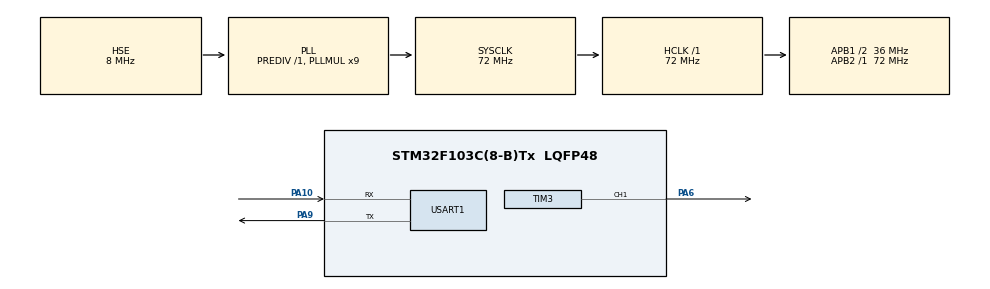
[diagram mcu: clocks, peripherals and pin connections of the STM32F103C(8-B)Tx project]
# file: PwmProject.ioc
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Mcu.Family=STM32F1
RCC.PLLSourceVirtual=RCC_PLLSOURCE_HSE
PD1-OSC_OUT.Mode=HSE-External-Oscillator
PA10.Mode=Asynchronous
PD0-OSC_IN.Signal=RCC_OSC_IN
RCC.APB1CLKDivider=RCC_HCLK_DIV2
RCC.SYSCLKSource=RCC_SYSCLKSOURCE_PLLCLK
ProjectManager.StackSize=0x400
PD1-OSC_OUT.Signal=RCC_OSC_OUT
PA13.Signal=SYS_JTMS-SWDIO
PA9.Mode=Asynchronous
ProjectManager.TargetToolchain=STM32CubeIDE
RCC.HCLKFreq_Value=72000000
RCC.APB2TimFreq_Value=72000000
TIM3.Period=199
PA9.Signal=USART1_TX
RCC.USBFreq_Value=72000000
RCC.AHBFreq_Value=72000000
TIM3.Channel-PWM\ Generation1\ CH1=TIM_CHANNEL_1
PD0-OSC_IN.Mode=HSE-External-Oscillator
board=custom
RCC.PLLMUL=RCC_PLL_MUL9
RCC.APB2Freq_Value=72000000
PA14.Mode=Serial_Wire
TIM3.Prescaler=7199
SH.S_TIM3_CH1.0=TIM3_CH1,PWM Generation1 CH1
PA13.Mode=Serial_Wire
Mcu.Name=STM32F103C(8-B)Tx
RCC.SYSCLKFreq_VALUE=72000000
Mcu.Package=LQFP48
PA6.Signal=S_TIM3_CH1
USART1.VirtualMode=VM_ASYNC
PA10.Signal=USART1_RX
PA14.Signal=SYS_JTCK-SWCLK
ProjectManager.HeapSize=0x200
NVIC.PriorityGroup=NVIC_PRIORITYGROUP_4
RCC.APB1TimFreq_Value=72000000
NVIC.USART1_IRQn=true\:0\:0\:false\:false\:true\:true\:true
RCC.APB1Freq_Value=36000000
VP_TIM3_VS_ClockSourceINT.Mode=Internal

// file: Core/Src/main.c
/* USER CODE BEGIN Header */
/**
  ******************************************************************************
  * @file           : main.c
  * @brief          : Main program body
  ******************************************************************************
  * @attention
  *
  * <h2><center>&copy; Copyright (c) 2021 STMicroelectronics.
  * All rights reserved.</center></h2>
  *
  * This software component is licensed by ST under BSD 3-Clause license,
  * the "License"; You may not use this file except in compliance with the
  * License. You may obtain a copy of the License at:
  *                        opensource.org/licenses/BSD-3-Clause
  *
  ******************************************************************************
  */
/* USER CODE END Header */
#include "main.h"
#include "tim.h"
#include "usart.h"
#include "gpio.h"

/* USER CODE BEGIN Includes */
void Servo_Control(uint16_t angle){
	float temp;
	temp = (1.0 / 9.0) * angle + 5.0; // 占空比 = 1/9 * 角度 +5
	__HAL_TIM_SET_COMPARE(&htim3,TIM_CHANNEL_1,(uint16_t)temp);
}
/* USER CODE END Includes */

void SystemClock_Config(void);

/* USER CODE BEGIN 0 */
uint8_t RxBuffer[1];
uint8_t mode,dir,count;
/* USER CODE END 0 */

int main(void)
{

  /* MCU Configuration--------------------------------------------------------*/

  /* Reset of all peripherals, Initializes the Flash interface and the Systick. */
  HAL_Init();

  /* Configure the system clock */
  SystemClock_Config();

  /* Initialize all configured peripherals */
  MX_GPIO_Init();
  MX_TIM3_Init();
  MX_USART1_UART_Init();
  HAL_TIM_PWM_Start(&htim3, TIM_CHANNEL_1);
  HAL_UART_Receive_IT(&huart1, RxBuffer, 1);

  /* Infinite loop */
  while (1)
  {

    /* USER CODE BEGIN 3 */
	  if(mode == '1'){
		  Servo_Control(150);
		  HAL_Delay(2000);
		  Servo_Control(0);
		  mode = '0';
	  }
//	     Servo_Control(10);
//	    HAL_Delay(100);
//	    Servo_Control(20);
//	    HAL_Delay(100);
//	    Servo_Control(30);
//	    HAL_Delay(100);
//	    Servo_Control(40);
//	    HAL_Delay(100);
//	    Servo_Control(50);
//	    HAL_Delay(100);
//	    Servo_Control(60);
//	    HAL_Delay(100);
//	    Servo_Control(70);
//	    HAL_Delay(100);
//	    Servo_Control(80);
//	    HAL_Delay(100);
//	    Servo_Control(90);
//	    HAL_Delay(100);
//	    Servo_Control(0);
//	    HAL_Delay(1000);
  }
  /* USER CODE END 3 */
}

void SystemClock_Config(void)
{
  RCC_OscInitTypeDef RCC_OscInitStruct = {0};
  RCC_ClkInitTypeDef RCC_ClkInitStruct = {0};

  /** Initializes the RCC Oscillators according to the specified parameters
  * in the RCC_OscInitTypeDef structure.
  */
  RCC_OscInitStruct.OscillatorType = RCC_OSCILLATORTYPE_HSE;
  RCC_OscInitStruct.HSEState = RCC_HSE_ON;
  RCC_OscInitStruct.HSEPredivValue = RCC_HSE_PREDIV_DIV1;
  RCC_OscInitStruct.HSIState = RCC_HSI_ON;
  RCC_OscInitStruct.PLL.PLLState = RCC_PLL_ON;
  RCC_OscInitStruct.PLL.PLLSource = RCC_PLLSOURCE_HSE;
  RCC_OscInitStruct.PLL.PLLMUL = RCC_PLL_MUL9;
  if (HAL_RCC_OscConfig(&RCC_OscInitStruct) != HAL_OK)
  {
    Error_Handler();
  }
  /** Initializes the CPU, AHB and APB buses clocks
  */
  RCC_ClkInitStruct.ClockType = RCC_CLOCKTYPE_HCLK|RCC_CLOCKTYPE_SYSCLK
                              |RCC_CLOCKTYPE_PCLK1|RCC_CLOCKTYPE_PCLK2;
  RCC_ClkInitStruct.SYSCLKSource = RCC_SYSCLKSOURCE_PLLCLK;
  RCC_ClkInitStruct.AHBCLKDivider = RCC_SYSCLK_DIV1;
  RCC_ClkInitStruct.APB1CLKDivider = RCC_HCLK_DIV2;
  RCC_ClkInitStruct.APB2CLKDivider = RCC_HCLK_DIV1;

  if (HAL_RCC_ClockConfig(&RCC_ClkInitStruct, FLASH_LATENCY_2) != HAL_OK)
  {
    Error_Handler();
  }
}

/* USER CODE BEGIN 4 */
void HAL_UART_RxCpltCallback(UART_HandleTypeDef *huart){
	HAL_UART_Receive_IT(&huart1, RxBuffer, 1);
	mode = RxBuffer[0];
	HAL_UART_Transmit(&huart1,RxBuffer,3,100);
}
/* USER CODE END 4 */

void Error_Handler(void)
{
  __disable_irq();
  while (1)
  {
  }
}

/************************ (C) COPYRIGHT STMicroelectronics *****END OF FILE****/
